# VPAC0_COMMON_0_IVPAC_TOP_0_CFG_SLV_PAR_VPAC_VISS0_S_VBUSP_VISS_PCID_S_VBUSP_MMRCFG_PCID register map
Vendor: Texas Instruments
Peripheral module from a debugger description file (folder am62A).
Registers are 32-bit, read-write, reset 0x0 unless marked. A register's access mark holds for its fields unless they carry their own. Offsets are as the file gives them; lines under a group give offsets from that group; [hi:lo] are bit positions; {n}, {i} and the like mark numbered series; 'fields as' and 'values as' point back to an identical list; <NAME> marks a mode.

## VPAC0_COMMON_0_IVPAC_TOP_0_CFG_SLV_PAR_VPAC_VISS0_S_VBUSP_VISS_PCID_S_VBUSP_MMRCFG_PCID
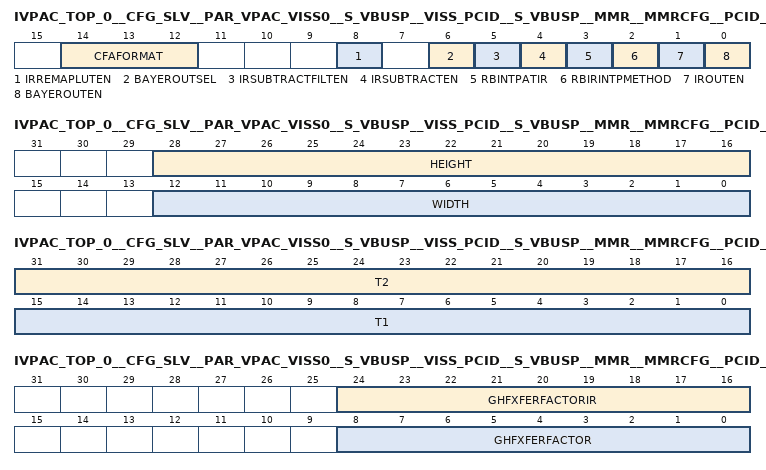
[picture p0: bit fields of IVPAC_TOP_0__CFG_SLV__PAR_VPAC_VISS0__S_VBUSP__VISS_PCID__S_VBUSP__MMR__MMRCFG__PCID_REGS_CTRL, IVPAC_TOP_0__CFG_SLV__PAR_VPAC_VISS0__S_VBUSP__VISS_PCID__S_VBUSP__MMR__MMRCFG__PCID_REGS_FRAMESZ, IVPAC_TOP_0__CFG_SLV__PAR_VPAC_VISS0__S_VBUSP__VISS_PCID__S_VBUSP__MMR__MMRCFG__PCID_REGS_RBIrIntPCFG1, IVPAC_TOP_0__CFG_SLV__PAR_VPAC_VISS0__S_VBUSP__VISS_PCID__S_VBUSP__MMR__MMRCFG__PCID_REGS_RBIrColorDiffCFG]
0x04 IVPAC_TOP_0__CFG_SLV__PAR_VPAC_VISS0__S_VBUSP__VISS_PCID__S_VBUSP__MMR__MMRCFG__PCID_REGS_CTRL — Control Register to Enable/Disable and select modes of operation
  [14:12] CFAFORMAT — Position of RED in first 4x2 window of 4x4 pixel RGBIR pixel pattern. configure such that RED pixel will be at [row%2]*4+col%4 in 4x4 RGBIR pixel pattern
  [8] IRREMAPLUTEN — Enable for IR Remap LUT. 0 : Disable IR remap LUT. IR data sent directly 1 : Enable IR Remap LUT function
  [6] BAYEROUTSEL — Control to select Bayer or IR to output on Bayer output channel. 0 : IR Subtracted bayer is sent 1: Pre Remap Lut IR is sent
  [5] IRSUBTRACTFILTEN — Control for smoothening filtering of IR Subtraction Factor. 0 : smoothening Filter is disabled 1 : smoothening Filter is enabled Valid when IRSubtractEn is set
  [4] IRSUBTRACTEN — Control for IR Subtraction from Bayer output. 0 : IR subtraction from Bayer is disabled 1 : IR subtraction from Bayer is enabled
  [3] RBINTPATIR — Output color on IR pixels. 0 : Interpolate B at IR positions and R at B locations 1: Interpolate R at IR positions and B at R locations
  [2] RBIRINTPMETHOD — Interpolation method used for RB and IR upsampling interpolation. 0 : Constant Hue 1 : Color Difference
  [1] IROUTEN — Control to output IR Output Channel by PCID block. 0 : Disable 1 : Enable Note that IR needs to calculated internally for IR subtraction
  [0] BAYEROUTEN — Control to output data on Bayer Output Channel by PCID block. 0 : Disable 1 : Enable
0x08 IVPAC_TOP_0__CFG_SLV__PAR_VPAC_VISS0__S_VBUSP__VISS_PCID__S_VBUSP__MMR__MMRCFG__PCID_REGS_FRAMESZ — Actual frame size is configured value + 1
  [28:16] HEIGHT — Number of Lines per frame. Actual Frame height is HEIGHT +1. Actual frame height should minimum of 32 and multiple of 4. Max width supported is 8188
  [12:0] WIDTH — Number of pixels per line. Actual Frame width is WIDTH +1. Actual frame width should minimum of 64 and multiple of 4. Max width supported by logic is 8192 and limited by line memory size of 2688
0x0C IVPAC_TOP_0__CFG_SLV__PAR_VPAC_VISS0__S_VBUSP__VISS_PCID__S_VBUSP__MMR__MMRCFG__PCID_REGS_RBIrIntPCFG1 — Threshold Configuration for R/B/Ir interpoaltion processing
  [31:16] T2 — T2 Threshold in U16 format.
  [15:0] T1 — T1 Threshold in U16 format. Recommandated T1 < T2 < T3
0x10 IVPAC_TOP_0__CFG_SLV__PAR_VPAC_VISS0__S_VBUSP__VISS_PCID__S_VBUSP__MMR__MMRCFG__PCID_REGS_RBIrIntPCFG2 — Threshold Configuration for R/B/Ir interpoaltion processing
  [15:0] T3 — T3 Threshold in U16 format.
0x14 IVPAC_TOP_0__CFG_SLV__PAR_VPAC_VISS0__S_VBUSP__VISS_PCID__S_VBUSP__MMR__MMRCFG__PCID_REGS_RBIrColorDiffCFG — Portion of green high frequency component mixed with interpolated R/B/Ir
  [24:16] GHFXFERFACTORIR — Portion of green high frequency component mixed with interpolated Ir values in color difference IR interpolation method in U9Q8 format. Max value supported is 256
  [8:0] GHFXFERFACTOR — Portion of green high frequency component mixed with interpolated R/B values in color difference R/B interpolation Method in U9Q8 format. Max value supported is 256
0x18 IVPAC_TOP_0__CFG_SLV__PAR_VPAC_VISS0__S_VBUSP__VISS_PCID__S_VBUSP__MMR__MMRCFG__PCID_REGS_IRSubCFG1 — IR Subtraction Configuration1 Register
  [15:0] CUTOFFTH — Threshold for Ir subtraction in U16 format. When R/G/B pixel values at a locations in the input are above this threshold no IR subtraction is performed (i.e. Ir subtraction factor == 0)
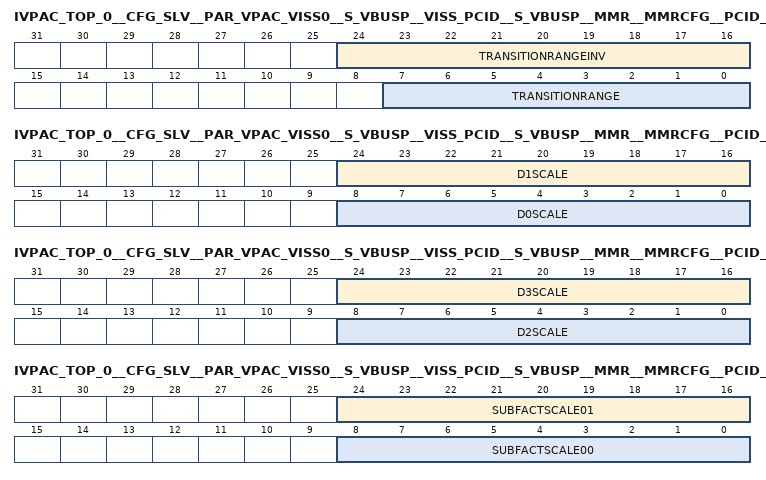
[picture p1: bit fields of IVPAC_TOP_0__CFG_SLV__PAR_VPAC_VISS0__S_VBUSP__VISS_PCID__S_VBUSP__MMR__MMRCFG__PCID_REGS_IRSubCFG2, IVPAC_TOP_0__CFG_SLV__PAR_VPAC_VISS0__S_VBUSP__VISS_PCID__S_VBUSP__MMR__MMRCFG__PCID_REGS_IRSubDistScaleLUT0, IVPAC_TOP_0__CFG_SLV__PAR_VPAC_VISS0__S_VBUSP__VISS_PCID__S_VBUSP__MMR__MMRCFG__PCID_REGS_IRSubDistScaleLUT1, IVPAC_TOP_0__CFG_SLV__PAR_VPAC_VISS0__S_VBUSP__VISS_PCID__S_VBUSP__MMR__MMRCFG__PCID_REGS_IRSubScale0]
0x1C IVPAC_TOP_0__CFG_SLV__PAR_VPAC_VISS0__S_VBUSP__VISS_PCID__S_VBUSP__MMR__MMRCFG__PCID_REGS_IRSubCFG2 reset 0x1000000 — IR Subtraction Configuration1 Register
  [24:16] TRANSITIONRANGEINV — Reciprocal of TransitionRange in U9Q8 format (i.e. 8-bit of decimal with 1-bit of integer). SW driver needs to generate this from TransitionRange to avoid HW divider
  [7:0] TRANSITIONRANGE — Range of gray levels just below IRSubCFG1.Thrshld where Ir subtraction factor linearly changes from 1 at IRSubCFG1.Thrshld - IRSubCFG2.TransitionRange and 0 above IRSubCFG1.Thrshld. Is in U8 format
0x20 IVPAC_TOP_0__CFG_SLV__PAR_VPAC_VISS0__S_VBUSP__VISS_PCID__S_VBUSP__MMR__MMRCFG__PCID_REGS_IRSubDistScaleLUT0 reset 0x1000100 — City Block Distance based IR Subtraction Scale factor LUT. Scales are used in Pre smoothing filter factor calculation
  [24:16] D1SCALE — L1 norm of City Block Distance 1 Scale Filter. Max value supported is 256
  [8:0] D0SCALE — L1 norm of City Block Distance 0 Scale Filter. Max value supported is 256
0x24 IVPAC_TOP_0__CFG_SLV__PAR_VPAC_VISS0__S_VBUSP__VISS_PCID__S_VBUSP__MMR__MMRCFG__PCID_REGS_IRSubDistScaleLUT1 reset 0x8000C0 — Distance based IR Subtraction Scale factor LUT. Scales are used in Pre smoothing filter factor calculation
  [24:16] D3SCALE — L1 norm of City Block Distance 3 Scale Filter. Max value supported is 256
  [8:0] D2SCALE — L1 norm of City Block Distance 2 Scale Filter. Max value supported is 256
0x28 IVPAC_TOP_0__CFG_SLV__PAR_VPAC_VISS0__S_VBUSP__VISS_PCID__S_VBUSP__MMR__MMRCFG__PCID_REGS_IRSubDistScaleLUT2 reset 0x40 — Distance based IR Subtraction Scale factor LUT. Scales are used in Pre smoothing filter factor calculation
  [8:0] D4SCALE — L1 norm of City Block Distance 4 Scale Filter. Max value supported is 256
0x2C IVPAC_TOP_0__CFG_SLV__PAR_VPAC_VISS0__S_VBUSP__VISS_PCID__S_VBUSP__MMR__MMRCFG__PCID_REGS_IRSubScale0 reset 0x1000100 — IR Subtraction Factor after smoothening Factor Filter
  [24:16] SUBFACTSCALE01 — Ir Subtraction factor scale for [0][1] co-ordinates in Bayer 2x2 pattern. Represented in U9Q8 format and Max value supported is 511
  [8:0] SUBFACTSCALE00 — Ir Subtraction factor scale for [0][0] co-ordinates in Bayer 2x2 pattern. Represented in U9Q8 format and Max value supported is 511
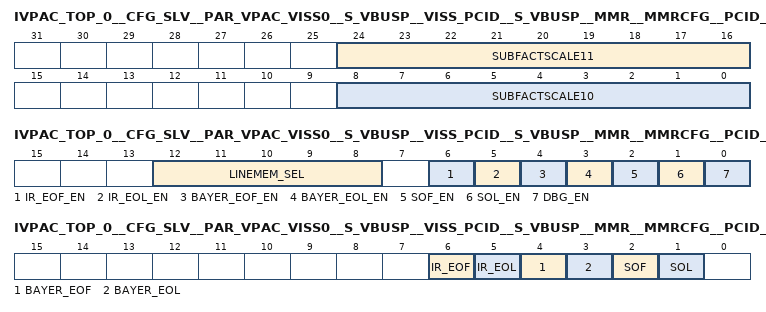
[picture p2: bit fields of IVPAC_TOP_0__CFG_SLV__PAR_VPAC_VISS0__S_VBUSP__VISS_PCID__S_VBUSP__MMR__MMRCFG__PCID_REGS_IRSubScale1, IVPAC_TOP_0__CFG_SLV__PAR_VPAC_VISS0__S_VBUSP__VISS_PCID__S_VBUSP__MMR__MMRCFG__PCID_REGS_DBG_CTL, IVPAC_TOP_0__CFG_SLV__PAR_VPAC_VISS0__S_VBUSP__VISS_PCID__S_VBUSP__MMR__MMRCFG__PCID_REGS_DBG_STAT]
0x30 IVPAC_TOP_0__CFG_SLV__PAR_VPAC_VISS0__S_VBUSP__VISS_PCID__S_VBUSP__MMR__MMRCFG__PCID_REGS_IRSubScale1 reset 0x1000100 — IR Subtraction Factor after smoothening Factor Filter
  [24:16] SUBFACTSCALE11 — Ir Subtraction factor scale for [1][1] co-ordinates in Bayer 2x2 pattern. Represented in U9Q8 format and Max value supported is 511
  [8:0] SUBFACTSCALE10 — Ir Subtraction factor scale for [1][0] co-ordinates in Bayer 2x2 pattern. Represented in U9Q8 format and Max value supported is 511
0x80 IVPAC_TOP_0__CFG_SLV__PAR_VPAC_VISS0__S_VBUSP__VISS_PCID__S_VBUSP__MMR__MMRCFG__PCID_REGS_INT_STAT access not given — Set on internal interupt event and clr by SW
  [0] LUT_CFG_ERR — status/clear for mmr configuration error. Set when Config access happen to LUT memory in the middle of processing (access R/W1TC)
0x100 IVPAC_TOP_0__CFG_SLV__PAR_VPAC_VISS0__S_VBUSP__VISS_PCID__S_VBUSP__MMR__MMRCFG__PCID_REGS_DBG_CTL — Control the memory access selection
  [12:8] LINEMEM_SEL — Select Line memory to do MMR access. 0 - 7 : Input Line buffer (32-bit max_line_width/2 entries) 8 - 12 : Up-Sampled new green pixel Line memory (32-bit max_line_width/4 entries) 13 - 17 : IR Subtraction Factor Line memory (18-bit max_line_width/2 entries)
  [6] IR_EOF_EN — Enable for EOF at PCID IR output channel
  [5] IR_EOL_EN — Enable for EOL at PCID IR output channel
  [4] BAYER_EOF_EN — Enable for EOF at PCID Bayer output channel
  [3] BAYER_EOL_EN — Enable for EOL at PCID Bayer output channel
  [2] SOF_EN — Enable for SOF at PCID input
  [1] SOL_EN — Enable for SOL at PCID input
  [0] DBG_EN — Enable debug features, set to '0' to disable all debug events
0x104 IVPAC_TOP_0__CFG_SLV__PAR_VPAC_VISS0__S_VBUSP__VISS_PCID__S_VBUSP__MMR__MMRCFG__PCID_REGS_DBG_STAT access not given — Set/Clear for PCID debug events and corresponding event capture is enabled in DBG_CTL register
  [6] IR_EOF — Status/Clear for EOF at PCID IR output channel. Set on EOF at PCID IR output channel (access R/W1TC)
  [5] IR_EOL — Status/Clear for EOL at PCID IR output channel. Set on EOL at PCID IR output channel (access R/W1TC)
  [4] BAYER_EOF — Status/Clear for EOF at PCID Bayer output channel. Set on EOF at PCID Bayer output channel (access R/W1TC)
  [3] BAYER_EOL — Status/Clear for EOL at PCID Bayer output channel. Set on EOL at PCID Bayer output channel (access R/W1TC)
  [2] SOF — Status/Clear for SOF at PCID input. Set on SOF at PCID input (access R/W1TC)
  [1] SOL — Status/Clear for SOL at PCID input. Set on SOL at PCID input (access R/W1TC)
